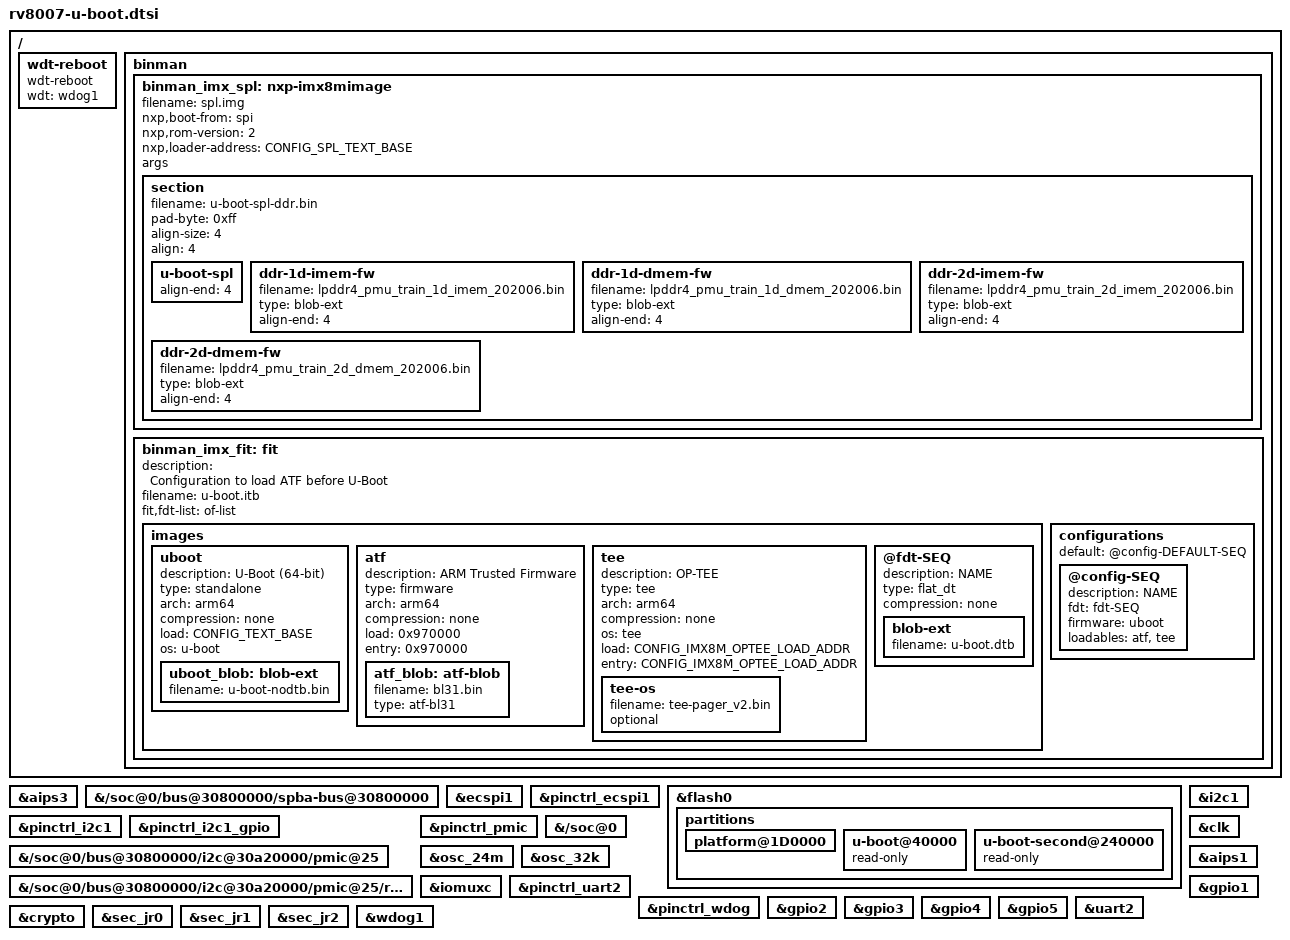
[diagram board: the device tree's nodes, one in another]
// SPDX-License-Identifier: GPL-2.0+
/*
 * Copyright 2025 Akkodis Edge Sweden AB
 */

/ {
	wdt-reboot {
		compatible = "wdt-reboot";
		wdt = <&wdog1>;
		bootph-pre-ram;
	};

	binman {
		binman_imx_spl: nxp-imx8mimage {
				filename = "spl.img";
				nxp,boot-from = "spi";
				nxp,rom-version = <2>;
				nxp,loader-address = <CONFIG_SPL_TEXT_BASE>;
				args;	/* Needed by mkimage etype superclass */

				section {
					filename = "u-boot-spl-ddr.bin";
					pad-byte = <0xff>;
					align-size = <4>;
					align = <4>;

					u-boot-spl {
						align-end = <4>;
					};

					ddr-1d-imem-fw {
						filename = "lpddr4_pmu_train_1d_imem_202006.bin";
						type = "blob-ext";
						align-end = <4>;
					};

					ddr-1d-dmem-fw {
						filename = "lpddr4_pmu_train_1d_dmem_202006.bin";
						type = "blob-ext";
						align-end = <4>;
					};

					ddr-2d-imem-fw {
						filename = "lpddr4_pmu_train_2d_imem_202006.bin";
						type = "blob-ext";
						align-end = <4>;
					};

					ddr-2d-dmem-fw {
						filename = "lpddr4_pmu_train_2d_dmem_202006.bin";
						type = "blob-ext";
						align-end = <4>;
					};
				};
			};

		binman_imx_fit: fit {
			description = "Configuration to load ATF before U-Boot";
			filename = "u-boot.itb";
			fit,fdt-list = "of-list";
			#address-cells = <1>;

			images {
				uboot {
					description = "U-Boot (64-bit)";
					type = "standalone";
					arch = "arm64";
					compression = "none";
					load = <CONFIG_TEXT_BASE>;
					os = "u-boot";

					uboot_blob: blob-ext {
						filename = "u-boot-nodtb.bin";
					};
				};

				atf {
					description = "ARM Trusted Firmware";
					type = "firmware";
					arch = "arm64";
					compression = "none";
					load = <0x970000>;
					entry = <0x970000>;

					atf_blob: atf-blob {
						filename = "bl31.bin";
						type = "atf-bl31";
					};
				};

				tee: tee {
					description = "OP-TEE";
					type = "tee";
					arch = "arm64";
					compression = "none";
					os = "tee";
					load = <CONFIG_IMX8M_OPTEE_LOAD_ADDR>;
					entry = <CONFIG_IMX8M_OPTEE_LOAD_ADDR>;

					tee-os {
						filename = "tee-pager_v2.bin";
						optional;
					};
				};

				@fdt-SEQ {
					description = "NAME";
					type = "flat_dt";
					compression = "none";

					blob-ext {
						filename = "u-boot.dtb";
					};
				};
			};

			configurations {
				default = "@config-DEFAULT-SEQ";

				@config-SEQ {
					description = "NAME";
					fdt = "fdt-SEQ";
					firmware = "uboot";
					loadables = "atf", "tee";
				};
			};
		};
	};
};

&aips3 {
	bootph-pre-ram;
};

&{/soc@0/bus@30800000/spba-bus@30800000} {
	bootph-pre-ram;
};

&ecspi1 {
	bootph-pre-ram;
};

&pinctrl_ecspi1 {
	bootph-pre-ram;
};

&flash0 {
	bootph-pre-ram;
	partitions {
		bootph-pre-ram;
		platform@1D0000 {
			bootph-pre-ram;
		};
		u-boot@40000 {
			bootph-pre-ram;
			read-only;
		};
		u-boot-second@240000 {
			bootph-pre-ram;
			read-only;
		};
	};
};

&i2c1 {
	bootph-pre-ram;
};

&pinctrl_i2c1 {
	bootph-pre-ram;
};

&pinctrl_i2c1_gpio {
	bootph-pre-ram;
};

&{/soc@0/bus@30800000/i2c@30a20000/pmic@25} {
	bootph-pre-ram;
};

&{/soc@0/bus@30800000/i2c@30a20000/pmic@25/regulators} {
	bootph-pre-ram;
};

&pinctrl_pmic {
	bootph-pre-ram;
};

&{/soc@0} {
	bootph-pre-ram;
};

&clk {
	bootph-pre-ram;
	/delete-property/ assigned-clocks;
	/delete-property/ assigned-clock-parents;
	/delete-property/ assigned-clock-rates;
};

&osc_24m {
	bootph-pre-ram;
};

&osc_32k {
	bootph-pre-ram;
};

&aips1 {
	bootph-pre-ram;
};

&iomuxc {
	bootph-pre-ram;
};

&pinctrl_uart2 {
	bootph-pre-ram;
};

&pinctrl_wdog {
	bootph-pre-ram;
};

&gpio1 {
	bootph-pre-ram;
};

&gpio2 {
	bootph-pre-ram;
};

&gpio3 {
	bootph-pre-ram;
};

&gpio4 {
	bootph-pre-ram;
};

&gpio5 {
	bootph-pre-ram;
};

&uart2 {
	bootph-pre-ram;
};

&crypto {
	bootph-pre-ram;
};

&sec_jr0 {
	bootph-pre-ram;
};

&sec_jr1 {
	bootph-pre-ram;
};

&sec_jr2 {
	bootph-pre-ram;
};

&wdog1 {
	bootph-pre-ram;
};
